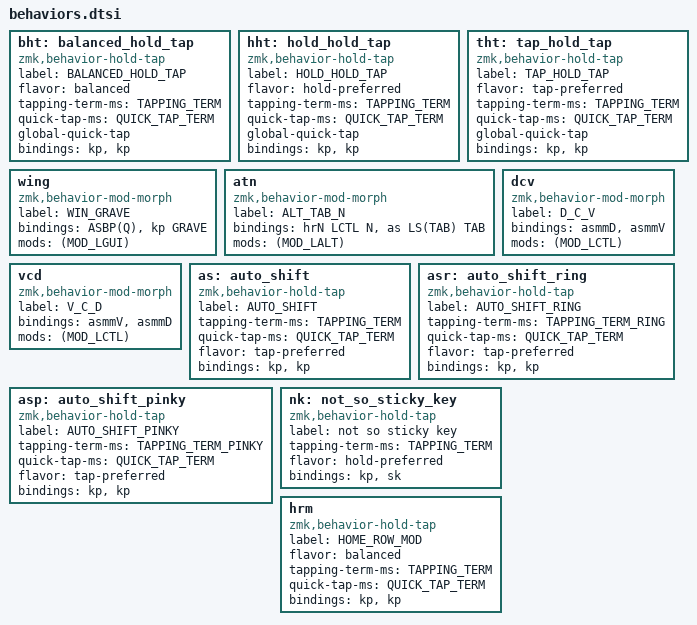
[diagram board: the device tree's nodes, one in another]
bht: balanced_hold_tap {
    compatible = "zmk,behavior-hold-tap";
    label = "BALANCED_HOLD_TAP";
    #binding-cells = <2>;
    flavor = "balanced";
    tapping-term-ms = <TAPPING_TERM>;
    quick-tap-ms = <QUICK_TAP_TERM>;
    global-quick-tap;
    bindings = <&kp>, <&kp>;
};

hht: hold_hold_tap {
    compatible = "zmk,behavior-hold-tap";
    label = "HOLD_HOLD_TAP";
    #binding-cells = <2>;
    flavor = "hold-preferred";
    tapping-term-ms = <TAPPING_TERM>;
    quick-tap-ms = <QUICK_TAP_TERM>;
    global-quick-tap;
    bindings = <&kp>, <&kp>;
};

tht: tap_hold_tap {
    compatible = "zmk,behavior-hold-tap";
    label = "TAP_HOLD_TAP";
    #binding-cells = <2>;
    flavor = "tap-preferred";
    tapping-term-ms = <TAPPING_TERM>;
    quick-tap-ms = <QUICK_TAP_TERM>;
    global-quick-tap;
    bindings = <&kp>, <&kp>;
};

wing: wing {
    compatible = "zmk,behavior-mod-morph";
    label = "WIN_GRAVE";
    #binding-cells = <0>;
    /* bindings = <AS(Q)>, <&kp GRAVE>; */
    bindings = <ASBP(Q)>, <&kp GRAVE>;
    mods = <(MOD_LGUI)>;
};

atn: atn {
    compatible = "zmk,behavior-mod-morph";
    label = "ALT_TAB_N";
    #binding-cells = <0>;
    bindings = <&hrN LCTL N>, <&as LS(TAB) TAB>;
    mods = <(MOD_LALT)>;
};

dcv: dcv {
    compatible = "zmk,behavior-mod-morph";
    label = "D_C_V";
    #binding-cells = <0>;
    bindings = <&asmmD>, <&asmmV>;
    mods = <(MOD_LCTL)>;
};

vcd: vcd {
    compatible = "zmk,behavior-mod-morph";
    label = "V_C_D";
    #binding-cells = <0>;
    bindings = <&asmmV>, <&asmmD>;
    mods = <(MOD_LCTL)>;
};

as: auto_shift {
    compatible = "zmk,behavior-hold-tap";
    label = "AUTO_SHIFT";
    #binding-cells = <2>;
    tapping-term-ms = <TAPPING_TERM>;
    quick-tap-ms = <QUICK_TAP_TERM>;
    flavor = "tap-preferred";
    bindings = <&kp>, <&kp>;
};

asr: auto_shift_ring {
    compatible = "zmk,behavior-hold-tap";
    label = "AUTO_SHIFT_RING";
    #binding-cells = <2>;
    tapping-term-ms = <TAPPING_TERM_RING>;
    quick-tap-ms = <QUICK_TAP_TERM>;
    flavor = "tap-preferred";
    bindings = <&kp>, <&kp>;
};

asp: auto_shift_pinky {
    compatible = "zmk,behavior-hold-tap";
    label = "AUTO_SHIFT_PINKY";
    #binding-cells = <2>;
    tapping-term-ms = <TAPPING_TERM_PINKY>;
    quick-tap-ms = <QUICK_TAP_TERM>;
    flavor = "tap-preferred";
    bindings = <&kp>, <&kp>;
};

nk: not_so_sticky_key {
    compatible = "zmk,behavior-hold-tap";
    label = "not so sticky key";
    #binding-cells = <2>;
    tapping-term-ms = <TAPPING_TERM>;
    flavor = "hold-preferred";
    bindings = <&kp>, <&sk>;
};

hrm: hrm {
    compatible = "zmk,behavior-hold-tap";
    label = "HOME_ROW_MOD";
    #binding-cells = <2>;
    flavor = "balanced";
    tapping-term-ms = <TAPPING_TERM>;
    quick-tap-ms = <QUICK_TAP_TERM>;
    bindings = <&kp>, <&kp>;
};

#define SK(KEY) &nk KEY KEY

#define HRA &hrm LSHIFT A
#define HRR &hrm LGUI R
#define HRS &hrm LALT S
#define HRT &hrm LCTL T
#define HRN &hrm LCTL N
#define HRE &hrm LALT E
#define HRI &hrm LGUI I
#define HRO &hrm LSHIFT O
